# GD32A72_A74x register map
File version: 1.0
CPU: CM7 r2p1, little endian, MPU, FPU, DSP, 4 interrupt priority bits
Registers are 32-bit, read-write, reset 0x0 unless marked. A register's access mark holds for its fields unless they carry their own. Offsets are from the block's base; [hi:lo] are bit positions; {n}, {i} and the like mark numbered series.

## ADC0 — Analog-to-digital converter
Base 0x4000F000
Same registers: ADC1 0x4000F800, ADC2 0x40012400
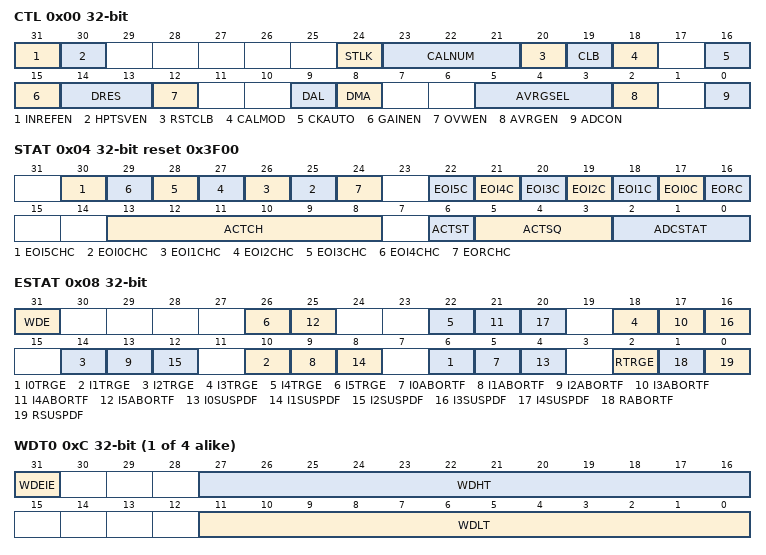
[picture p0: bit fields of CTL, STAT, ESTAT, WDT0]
0x00 CTL — Control register
  [31] INREFEN — Internal reference voltage enable
  [30] HPTSVEN — High-precision temperature sensor enable
  [24] STLK — Self test register lock
  [23:21] CALNUM — Calibration Times
  [20] RSTCLB — Reset calibration
  [19] CLB — ADC calibration
  [18] CALMOD — ADC calibration mode
  [16] CKAUTO — Clock automatic off
  [15] GAINEN — Gain mode enable
  [14:13] DRES — ADC data resolution
  [12] OVWEN — Overwrite enable
  [9] DAL — Data alignment
  [8] DMA — DMA request enable
  [5:3] AVRGSEL — AVRGSEL[2:0]
  [2] AVRGEN
  [0] ADCON
0x04 STAT access per field reset 0x3F00 — Status register
  [30] EOI5CHC rw — End of inserted sequence 5 channel conversion
  [n+25] EOI{n}CHC rw (n=0..4)
  [24] EORCHC rw
  [22] EOI5C rw — End of inserted sequence 5 conversion
  [21] EOI4C rw — End of inserted sequence 4 conversion
  [20] EOI3C rw — End of inserted sequence 3 conversion
  [19] EOI2C rw
  [18] EOI1C rw — End of inserted sequence 1 conversion
  [17] EOI0C rw
  [16] EORC rw
  [13:8] ACTCH ro — ACTCH[5:0]
  [6] ACTST ro
  [5:3] ACTSQ ro — ACTSQ[2:0]
  [2:0] ADCSTAT ro — ADC State
0x08 ESTAT access per field — Error status register
  [31] WDE rw — Analog Watchdog event flag
  [4n+6] I{n}TRGE rw (n=0..5) — Inserted sequence {n} trigger error
  [4n+5] I{n}ABORTF rw (n=0..5) — Inserted sequence {n} aborted flag
  [4n+4] I{n}SUSPDF ro (n=0..4) — Inserted sequence {n} suspended flag
  [2] RTRGE rw — Routine sequence trigger error
  [1] RABORTF rw — Routine sequence aborted flag
  [0] RSUSPDF ro — Routine sequence suspended flag
{0xC+4i} WDT{i} (i=0..3) — Watchdog threshold register {i}
  [31] WDEIE — Analog watchdog {i} interrupt enable
  [27:16] WDHT — High threshold for analog watchdog {i}
  [11:0] WDLT — Low threshold for analog watchdog {i}
0x1C PSMPCFG — Presampling time configure register
  [9:0] PSMP — ADC channel n pre-sample time
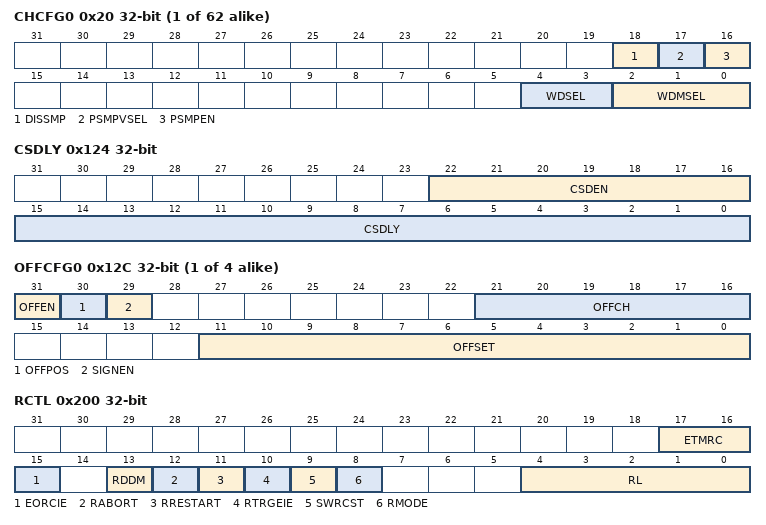
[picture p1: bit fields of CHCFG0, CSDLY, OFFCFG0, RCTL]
{0x20+4i} CHCFG{i} (i=0..61) — Channel configure register {i}
  [18] DISSMP — Disable channel n sampling
  [17] PSMPVSEL — ADC channel n pre-sample voltage select
  [16] PSMPEN — ADC channel n pre-sample enable
  [4:3] WDSEL — ADC channel n analog watchdog selection
  [2:0] WDMSEL — Analog watchdog mode select
0x118 WDINTF0 — Watchdog interrupt flag register 0
  [31:0] WDIF0 — Analog watchdog interrupt flag 0
0x11C WDINTF1 — Watchdog interrupt flag register 1
  [29:0] WDIF1 — Analog watchdog interrupt flag 1
0x120 EDDLY — External decode delay register
  [15:0] EDDLY — extenal analog multiplexers decode signals delay time
0x124 CSDLY — Conversion start delay register
  [22:16] CSDEN — the delay time from trigger to start conversion enable
  [15:0] CSDLY — the delay time from trigger to start conversion
0x128 GAINCFG — Gain configure register
  [13:0] GAIN — Gain factor
{0x12C+4i} OFFCFG{i} (i=0..3) — Offset configure register {i}
  [31] OFFEN — Offset {i} enable
  [30] OFFPOS — Positive offset
  [29] SIGNEN — Signed data enable
  [21:16] OFFCH — Channel selection for the data offset {i}
  [11:0] OFFSET — Offset factor
0x13C SYNCCTL — Sync control register
  [4:0] SYNCM — ADC sync mode
0x200 RCTL access per field — Routine sequence control register
  [17:16] ETMRC rw — external trigger mode for routine sequence
  [15] EORCIE rw — Interrupt enable for EORC
  [13] RDDM rw — routine sequence dma disable mode
  [12] RABORT wo — abort routine sequence current conversion
  [11] RRESTART rw — Restart routine sequence when the routine sequence be suspended
  [10] RTRGEIE rw — Interrupt enable for RTRGE
  [9] SWRCST wo — Software start on routine channel
  [8] RMODE rw — Routine sequence conversion mode
  [4:0] RL rw — Routine sequence length
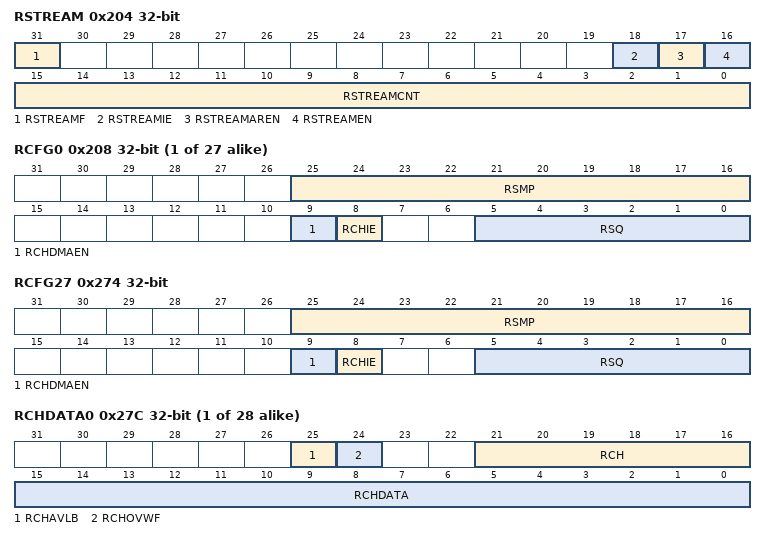
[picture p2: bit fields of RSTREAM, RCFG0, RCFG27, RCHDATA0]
0x204 RSTREAM — Routine sequence stream register
  [31] RSTREAMF — Routine sequence stream flag
  [18] RSTREAMIE — Routine sequence stream interrupt enable
  [17] RSTREAMAREN — Routine sequence stream counter value reload enable
  [16] RSTREAMEN — Routine sequence stream conversion enable
  [15:0] RSTREAMCNT — Routine sequence stream counter value
{0x208+4i} RCFG{i} (i=0..26) — Routine sequence configure register {i}
  [25:16] RSMP — Routine sequence channel {i} sample time
  [9] RCHDMAEN
  [8] RCHIE
  [5:0] RSQ — RSQ[5:0]
0x274 RCFG27 — Routine sequence configure register 27
  [25:16] RSMP — Routine sequence channel x sample time
  [9] RCHDMAEN — Routine sequence channel x DMA request enable
  [8] RCHIE — Routine sequence channel x interrupt enables for RCHIF or EORCHC
  [5:0] RSQ — The channel number n (n is from 0 to 61) is written to these bits to select a channel as the xth conversion in the routine sequence
0x278 RCHINTF — Routine sequence channel conversion end interrupt flag register
  [27:0] RCHIF — Routine sequence channel conversion end interrupt flag
{0x27C+4i} RCHDATA{i} ro (i=0..27) — Routine sequence channel data register {i}
  [25] RCHAVLB — Routine sequence channel {i} conversion data available
  [24] RCHOVWF — Routine sequence channel {i} conversion data overwritten flag
  [21:16] RCH — Routine sequence channel {i}
  [15:0] RCHDATA — Routine sequence channel {i} conversion data
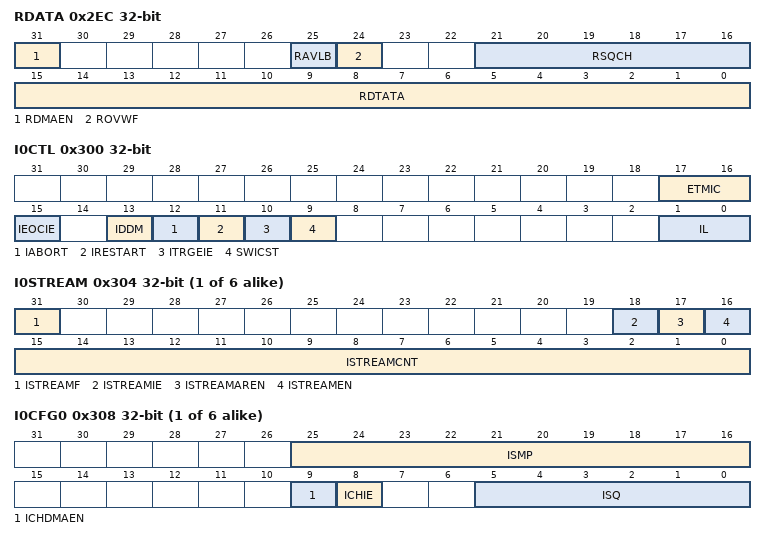
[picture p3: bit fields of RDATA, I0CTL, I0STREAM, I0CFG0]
0x2EC RDATA access per field — Routine sequence data register
  [31] RDMAEN rw — Routine sequence DMA request enable
  [25] RAVLB ro — Routine sequence conversion data available
  [24] ROVWF ro — Routine sequence conversion data overwritten flag
  [21:16] RSQCH ro — Routine sequence channel
  [15:0] RDTATA ro — Routine sequence conversion data
0x300 I0CTL access per field — Inserted sequence 0 control register
  [17:16] ETMIC rw — external trigger mode for inserted sequence
  [15] IEOCIE rw — Interrupt enable for EOIC
  [13] IDDM rw — inserted sequence dma disable mode
  [12] IABORT wo — abort inserted sequence m current conversion
  [11] IRESTART rw — restart inserted sequence m when inserted sequence m be suspended
  [10] ITRGEIE rw — Interrupt enable for ITRGE
  [9] SWICST wo — Software start on inserted channel
  [1:0] IL rw — Inserted sequence length
{0x304+0x50*i} I{i}STREAM (i=0..5) — Inserted sequence {i} stream register
  [31] ISTREAMF — Inserted sequence stream flag
  [18] ISTREAMIE
  [17] ISTREAMAREN
  [16] ISTREAMEN
  [15:0] ISTREAMCNT — ISTREAMCNT[15:0]
{0x308+0x50*i} I{i}CFG0 (i=0..5) — Inserted sequence {i} configure register 0
  [25:16] ISMP — Inserted sequence {i} channel 0 sample time
  [9] ICHDMAEN — Inserted sequence {i} channel 0 DMA request enable
  [8] ICHIE — nserted sequence {i} channel 0 interrupt enable for ICHIF or EOImCHC
  [5:0] ISQ — The channel number n
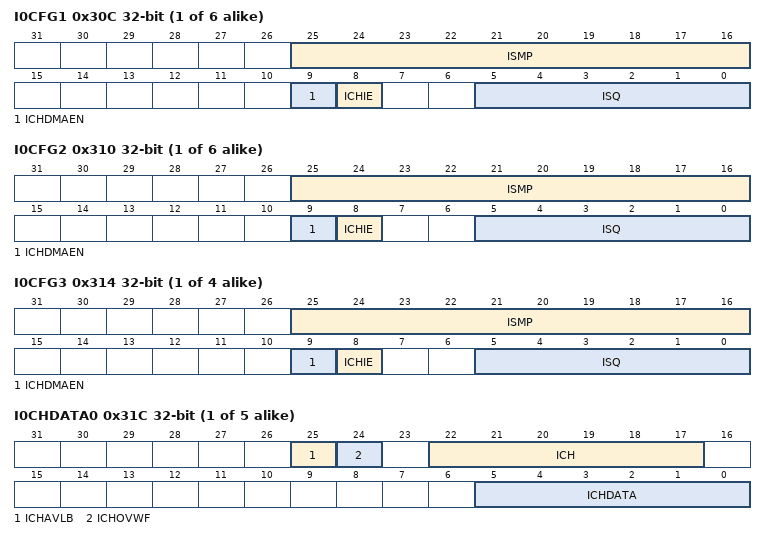
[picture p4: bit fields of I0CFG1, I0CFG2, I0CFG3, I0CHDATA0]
{0x30C+0x50*i} I{i}CFG1 (i=0..5) — Inserted sequence {i} configure register 1
  [25:16] ISMP — Inserted sequence {i} channel 1 sample time
  [9] ICHDMAEN — Inserted sequence {i} channel 1 DMA request enable
  [8] ICHIE — nserted sequence {i} channel 1 interrupt enable for ICHIF or EOImCHC
  [5:0] ISQ — The channel number n
{0x310+0x50*i} I{i}CFG2 (i=0..5) — Inserted sequence {i} configure register 2
  [25:16] ISMP — Inserted sequence {i} channel 2 sample time
  [9] ICHDMAEN — Inserted sequence {i} channel 2 DMA request enable
  [8] ICHIE — nserted sequence {i} channel 2 interrupt enable for ICHIF or EOImCHC
  [5:0] ISQ — The channel number n
{0x314+0x50*i} I{i}CFG3 (i=0..3) — Inserted sequence {i} configure register 3
  [25:16] ISMP — Inserted sequence {i} channel 3 sample time
  [9] ICHDMAEN — Inserted sequence {i} channel 3 DMA request enable
  [8] ICHIE — nserted sequence {i} channel 3 interrupt enable for ICHIF or EOImCHC
  [5:0] ISQ — The channel number n
{0x318+0x50*i} I{i}CHINTF (i=0..5) — Inserted sequence {i} channel conversion end interrupt flag register
  [3:0] ICHIF — Inserted sequence m channel conversion end interrupt flag
{0x31C+0x50*i} I{i}CHDATA0 (i=0..4) — Inserted sequence {i} channel data register 0
  [25] ICHAVLB — Inserted sequence {i} channel 0 conversion data available
  [24] ICHOVWF — Inserted sequence {i} channel 0 conversion data overwritten flag
  [22:17] ICH — Inserted sequence {i} channel 0
  [5:0] ICHDATA — Inserted sequence {i} channel 0 conversion data
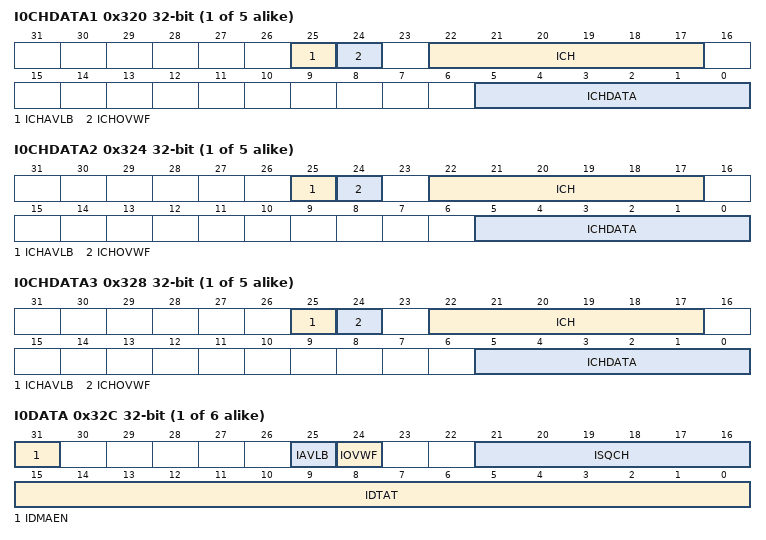
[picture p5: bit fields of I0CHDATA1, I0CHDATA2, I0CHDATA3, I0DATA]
{0x320+0x50*i} I{i}CHDATA1 (i=0..4) — Inserted sequence {i} channel data register 1
  [25] ICHAVLB — Inserted sequence {i} channel 1 conversion data available
  [24] ICHOVWF — Inserted sequence {i} channel 1 conversion data overwritten flag
  [22:17] ICH — Inserted sequence {i} channel 1
  [5:0] ICHDATA — Inserted sequence {i} channel 0 conversion data
{0x324+0x50*i} I{i}CHDATA2 (i=0..4) — Inserted sequence {i} channel data register 2
  [25] ICHAVLB — Inserted sequence {i} channel 2 conversion data available
  [24] ICHOVWF — Inserted sequence {i} channel 2 conversion data overwritten flag
  [22:17] ICH — Inserted sequence {i} channel 2
  [5:0] ICHDATA — Inserted sequence {i} channel 2 conversion data
{0x328+0x50*i} I{i}CHDATA3 (i=0..4) — Inserted sequence {i} channel data register 3
  [25] ICHAVLB — Inserted sequence {i} channel 3 conversion data available
  [24] ICHOVWF — Inserted sequence {i} channel 3 conversion data overwritten flag
  [22:17] ICH — Inserted sequence {i} channel 3
  [5:0] ICHDATA — Inserted sequence {i} channel 3 conversion data
{0x32C+0x50*i} I{i}DATA access per field (i=0..5) — Inserted sequence m data register
  [31] IDMAEN rw — Inserted sequence m DMA request enable
  [25] IAVLB ro — Inserted sequence m conversion data available
  [24] IOVWF ro — Inserted sequence m conversion data overwritten flag
  [21:16] ISQCH ro — Inserted sequence m channel
  [15:0] IDTAT ro — Inserted sequence m conversion data
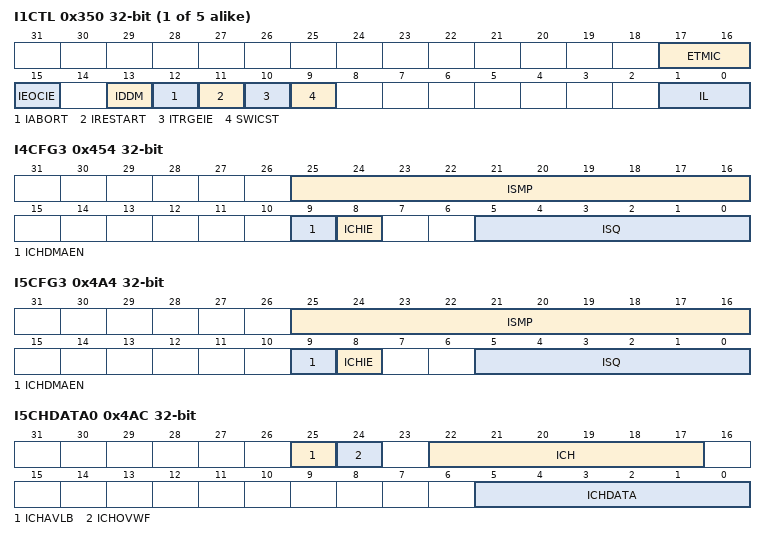
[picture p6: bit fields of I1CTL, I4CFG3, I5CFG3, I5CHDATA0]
{0x300+0x50*i} I{i}CTL access per field (i=1..5) — Inserted sequence {i} control register
  [17:16] ETMIC rw — External trigger mode for inserted channel
  [15] IEOCIE rw — Interrupt enable for EOIC
  [13] IDDM wo — Inserted sequence DMA disable mode
  [12] IABORT wo — Abort current inserted sequence conversion
  [11] IRESTART rw — Restart inserted sequence when inserted sequence m be suspended
  [10] ITRGEIE rw — Interrupt enable for ITRGE
  [9] SWICST wo — Software start on inserted channel
  [1:0] IL rw — Inserted sequence length
0x454 I4CFG3 — Inserted sequence 0 configure register 3
  [25:16] ISMP — Inserted sequence 4 channel 3 sample time
  [9] ICHDMAEN — Inserted sequence 4 channel 3 DMA request enable
  [8] ICHIE — nserted sequence 4 channel 3 interrupt enable for ICHIF or EOImCHC
  [5:0] ISQ — The channel number n
0x4A4 I5CFG3 — Inserted sequence 5 configure register 3
  [25:16] ISMP — Inserted sequence 5 channel 3 sample time
  [9] ICHDMAEN — Inserted sequence 5 channel 3 DMA request enable
  [8] ICHIE — nserted sequence 5 channel 3 interrupt enable for ICHIF or EOImCHC
  [5:0] ISQ — The channel number n
0x4AC I5CHDATA0 — Inserted sequence 4 channel data register 0
  [25] ICHAVLB — Inserted sequence 4 channel 0 conversion data available
  [24] ICHOVWF — Inserted sequence 4 channel 0 conversion data overwritten flag
  [22:17] ICH — Inserted sequence 4 channel 0
  [5:0] ICHDATA — Inserted sequence 4 channel 0 conversion data
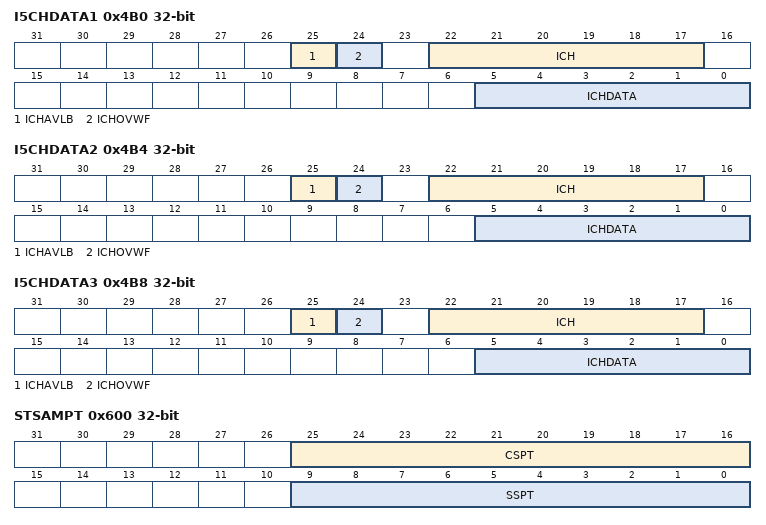
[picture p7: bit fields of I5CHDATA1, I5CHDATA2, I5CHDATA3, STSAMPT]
0x4B0 I5CHDATA1 — Inserted sequence 4 channel data register 1
  [25] ICHAVLB — Inserted sequence 4 channel 1 conversion data available
  [24] ICHOVWF — Inserted sequence 4 channel 1 conversion data overwritten flag
  [22:17] ICH — Inserted sequence 4 channel 1
  [5:0] ICHDATA — Inserted sequence 4 channel 0 conversion data
0x4B4 I5CHDATA2 — Inserted sequence 4 channel data register 2
  [25] ICHAVLB — Inserted sequence 4 channel 2 conversion data available
  [24] ICHOVWF — Inserted sequence 4 channel 2 conversion data overwritten flag
  [22:17] ICH — Inserted sequence 4 channel 2
  [5:0] ICHDATA — Inserted sequence 4 channel 2 conversion data
0x4B8 I5CHDATA3 — Inserted sequence 4 channel data register 3
  [25] ICHAVLB — Inserted sequence 4 channel 3 conversion data available
  [24] ICHOVWF — Inserted sequence 4 channel 3 conversion data overwritten flag
  [22:17] ICH — Inserted sequence 4 channel 3
  [5:0] ICHDATA — Inserted sequence 4 channel 3 conversion data
0x600 STSAMPT — Self test sample time register
  [25:16] CSPT — Sampling time for capacitive self test step
  [9:0] SSPT — Sampling time for supply self test step
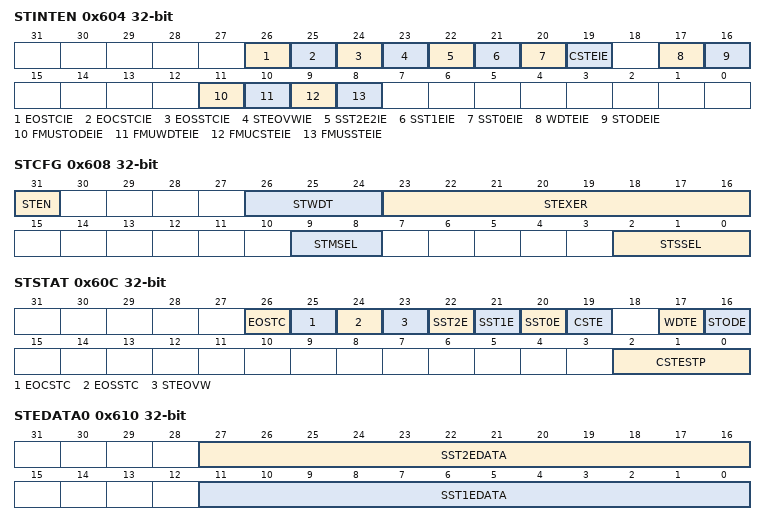
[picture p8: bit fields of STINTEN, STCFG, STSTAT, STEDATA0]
0x604 STINTEN — Self test interrupt enable register
  [26] EOSTCIE — Interrupt enable for EOSTC
  [25] EOCSTCIE — Interrupt enable for EOCSTC
  [24] EOSSTCIE — Interrupt enable for EOSSTC
  [23] STEOVWIE — Interrupt enable for STEOVW
  [22] SST2E2IE — Interrupt enable for SST2E
  [21] SST1EIE — Interrupt enable for SST1E
  [20] SST0EIE — Interrupt enable for SST0E
  [19] CSTEIE — Interrupt enable for CSTE
  [17] WDTEIE — Interrupt enable for WDTE
  [16] STODEIE — Interrupt enable for STODE
  [11] FMUSTODEIE — Interrupt enable for self test order error STODE to FMU
  [10] FMUWDTEIE — Interrupt enable for watchdog timer error WDTE to FMU
  [9] FMUCSTEIE — Interrupt enable for capacitive self test error CSTE to FMU
  [8] FMUSSTEIE — Interrupt enable for supply self test error SSTxE to FMU
0x608 STCFG — Self test configure register
  [31] STEN — Self test enable
  [26:24] STWDT — Self test watchdog timer
  [23:16] STEXER — Self test execution rate
  [9:8] STMSEL — Self test mode select
  [2:0] STSSEL — Capacitive and supply self test steps select in one shot mode
0x60C STSTAT access per field — Self test status register
  [26] EOSTC rw — End of self test conversion
  [25] EOCSTC rw — End of all capacitive self test steps conversion
  [24] EOSSTC rw — End of all supply self test steps conversion
  [23] STEOVW rw — Self test error overwrite
  [22] SST2E rw — Supply self test step 2 error
  [21] SST1E rw — Supply self test step 1 error
  [20] SST0E rw — Supply self test step 0 error
  [19] CSTE rw — Capacitive self test error
  [17] WDTE rw — Watchdog timer error
  [16] STODE rw — Self test order error
  [2:0] CSTESTP ro — Error step of capacitive self test
0x610 STEDATA0 ro — Self test error data register 0
  [27:16] SST2EDATA — Error data of supply self test step 2 conversion result
  [11:0] SST1EDATA — Error data of supply self test step 1 conversion result
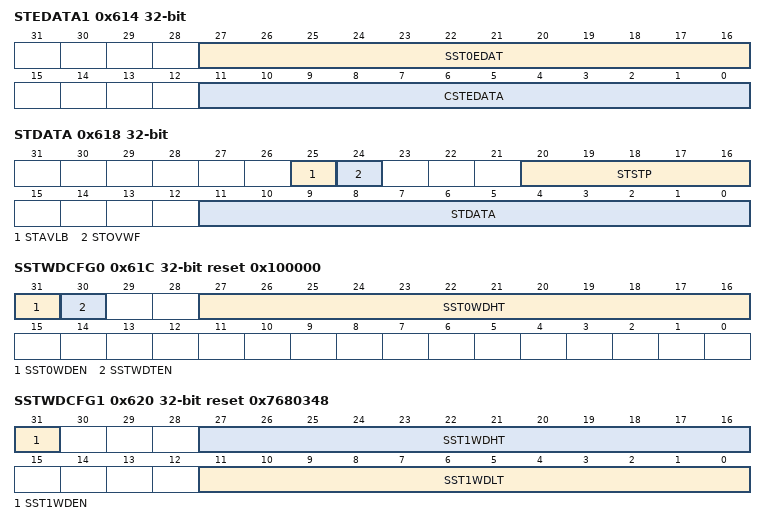
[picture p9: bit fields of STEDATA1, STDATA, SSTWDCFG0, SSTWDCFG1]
0x614 STEDATA1 ro — Self test error data register 1
  [27:16] SST0EDAT — Error data of supply self test step 0 conversion result
  [11:0] CSTEDATA — Error data of capactive self test step conversion result
0x618 STDATA ro — Self test conversion data register
  [25] STAVLB — Self test conversion data available
  [24] STOVWF — Self test conversion data overwritten flag
  [20:16] STSTP — Self test step
  [11:0] STDATA — Self test conversion data
0x61C SSTWDCFG0 reset 0x100000 — Watchdog for supply self test configure register 0
  [31] SST0WDEN — Supply self test step 0 watchdog enable
  [30] SSTWDTEN — Supply self test watchdog timer enable
  [27:16] SST0WDHT — Supply test step 0 analog watchdog high threshold value
0x620 SSTWDCFG1 reset 0x7680348 — Watchdog for supply self test configure register 1
  [31] SST1WDEN — Supply self test step 1 watchdog enable
  [27:16] SST1WDHT — Supply test step 1 analog watchdog high threshold value
  [11:0] SST1WDLT — Supply test step 1 analog watchdog low threshold value
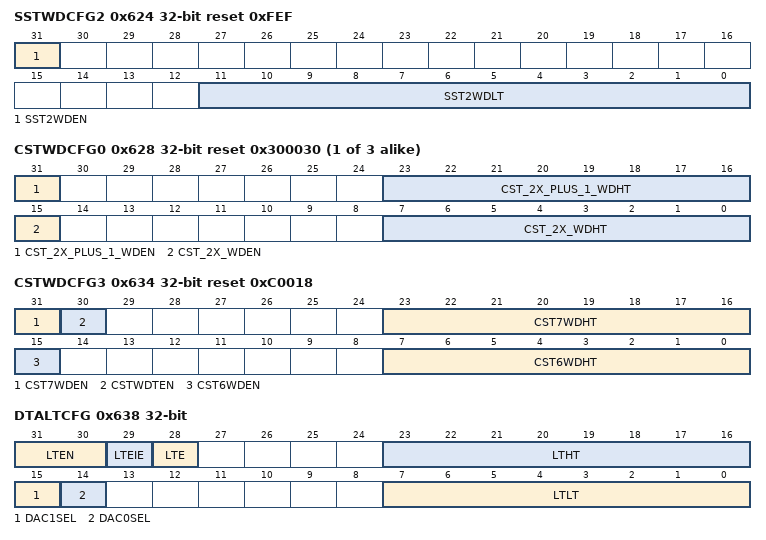
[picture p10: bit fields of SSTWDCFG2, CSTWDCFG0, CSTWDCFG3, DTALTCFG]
0x624 SSTWDCFG2 reset 0xFEF — Watchdog for supply self test configure register 2
  [31] SST2WDEN — Supply self test step 2 watchdog enable
  [11:0] SST2WDLT — Supply test step 2 analog watchdog low threshold value
{0x628+4i} CSTWDCFG{i} reset 0x300030 (i=0..2) — Watchdog for capacitive self test configure register x
  [31] CST_2X_PLUS_1_WDEN — Capacitive self test step (2x + 1) watchdog enable
  [23:16] CST_2X_PLUS_1_WDHT — Capacitive test step (2x + 1) analog watchdog high threshold value
  [15] CST_2X_WDEN — Capacitive self test step (2x) watchdog enable
  [7:0] CST_2X_WDHT — Capacitive test step (2x) analog watchdog high threshold value
0x634 CSTWDCFG3 reset 0xC0018 — Watchdog for capacitive self test configure register 3
  [31] CST7WDEN — Capacitive self test step 7 watchdog enable
  [30] CSTWDTEN — Capacitive self test watchdog timer enable
  [23:16] CST7WDHT — Capacitive test step 7 analog watchdog high threshold value
  [15] CST6WDEN — Capacitive self test step 6 watchdog enable
  [7:0] CST6WDHT — Capacitive test step 6 analog watchdog high threshold value
0x638 DTALTCFG — DAC to ADC loop test configure register
  [31:30] LTEN — DAC to ADC loop test enable
  [29] LTEIE — Interrupt enable for LTE
  [28] LTE — DAC to ADC loop test error
  [23:16] LTHT — DAC to ADC loop test high threshold value
  [15] DAC1SEL — Selsect DAC1_OUT as ADC input in DAC to ADC loop test mode
  [14] DAC0SEL — Selsect DAC0_OUT as ADC input in DAC to ADC loop test mode
  [7:0] LTLT — DAC to ADC loop test low threshold value
